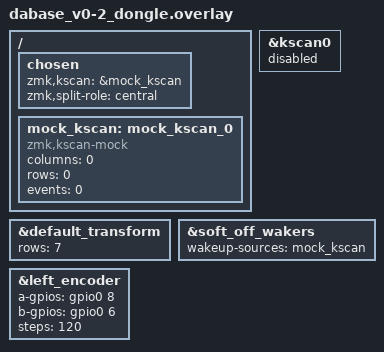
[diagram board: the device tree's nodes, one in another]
#include "dabase_v0-2.dtsi"
#include <dt-bindings/gpio/gpio.h>

/ {
    chosen {
        zmk,kscan = &mock_kscan;
        zmk,split-role = "central";
    };

    mock_kscan: mock_kscan_0 {
        compatible = "zmk,kscan-mock";
        columns = <0>;
        rows = <0>;
        events = <0>;
    };
};

&default_transform {
    rows = <7>;
};

&kscan0 {
    status = "disabled";
};

&soft_off_wakers {
    wakeup-sources = <&mock_kscan>;
};

&left_encoder {
    a-gpios = <&gpio0 8 (GPIO_ACTIVE_HIGH | GPIO_PULL_UP)>;
    b-gpios = <&gpio0 6 (GPIO_ACTIVE_HIGH | GPIO_PULL_UP)>;
    steps = <120>;
};
